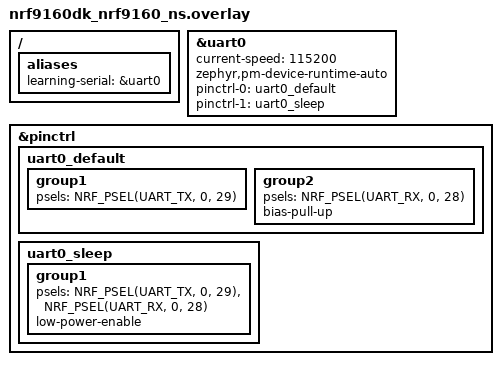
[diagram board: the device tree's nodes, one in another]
/{
    aliases {
        learning-serial = &uart0;
    };
};

&uart0 {
    status = "okay";
    current-speed = <115200>;
    /delete-property/ hw-flow-control;
    zephyr,pm-device-runtime-auto;
	pinctrl-0 = <&uart0_default>;
	pinctrl-1 = <&uart0_sleep>;
	pinctrl-names = "default", "sleep";
};

// write pinctrl again to remove RTS and CTS pin
&pinctrl {
	uart0_default: uart0_default {
		group1 {
			psels = <NRF_PSEL(UART_TX, 0, 29)>;
		};

		group2 {
			psels = <NRF_PSEL(UART_RX, 0, 28)>;
			bias-pull-up;
		};
	};

	uart0_sleep: uart0_sleep {
		group1 {
			psels = <NRF_PSEL(UART_TX, 0, 29)>,
				<NRF_PSEL(UART_RX, 0, 28)>;
			low-power-enable;
		};
	};
};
